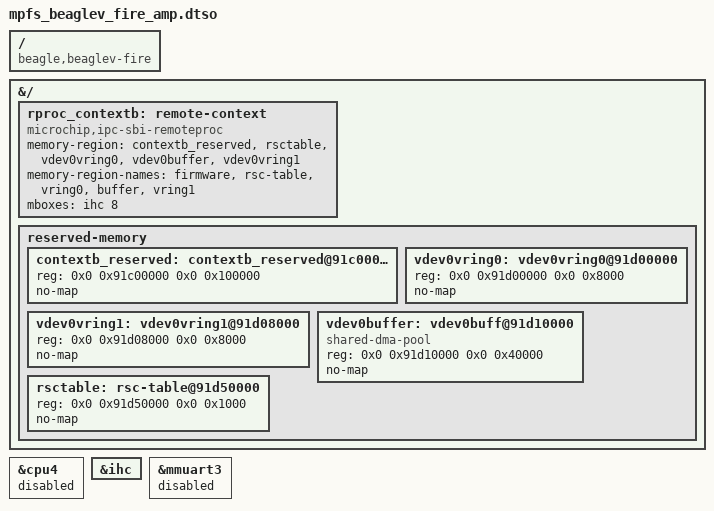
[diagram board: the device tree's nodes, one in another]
// SPDX-License-Identifier: (GPL-2.0+ OR MIT)
/*
 * Device Tree Overlay for BeagleV-Fire Asymmetric Multiprocessing (AMP)
 * 
 * Copyright (C) 2025 Microchip Technology Inc. and its subsidiaries.
 * Based on Icicle AMP overlay
 */

/dts-v1/;
/plugin/;

/ {
	compatible = "beagle,beaglev-fire", "microchip,mpfs";
};

&{/} {
	rproc_contextb: remote-context {
		compatible = "microchip,ipc-sbi-remoteproc";
		memory-region = <&contextb_reserved>, <&rsctable>,
				<&vdev0vring0>, <&vdev0buffer>,
				<&vdev0vring1>;
		memory-region-names = "firmware", "rsc-table",
				      "vring0", "buffer", "vring1";
		mboxes= <&ihc 8>;
		status = "okay";
	};

	reserved-memory {
		#address-cells = <2>;
		#size-cells = <2>;

		contextb_reserved: contextb_reserved@91c00000 {
			reg = <0x0 0x91c00000 0x0 0x100000>;
			no-map;
		};

		vdev0vring0: vdev0vring0@91d00000 {
			reg = <0x0 0x91d00000 0x0 0x8000>;
			no-map;
		};

		vdev0vring1: vdev0vring1@91d08000 {
			reg = <0x0 0x91d08000 0x0 0x8000>;
			no-map;
		};

		vdev0buffer: vdev0buff@91d10000 {
			compatible = "shared-dma-pool";
			reg = <0x0 0x91d10000 0x0 0x40000>;
			no-map;
		};

		rsctable: rsc-table@91d50000 {
			reg = <0x0 0x91d50000 0x0 0x1000>;
			no-map;
		};
	};
};

&cpu4 {
	status = "disabled"; // in use by context b
};

&ihc {
	status = "okay";
};

&mmuart3 {
	status = "disabled"; // in use by context b
};

/* Could not find wdt4 in the BeagleV-Fire kernel device tree blob
&wdt4 {
	status = "disabled";
};
*/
